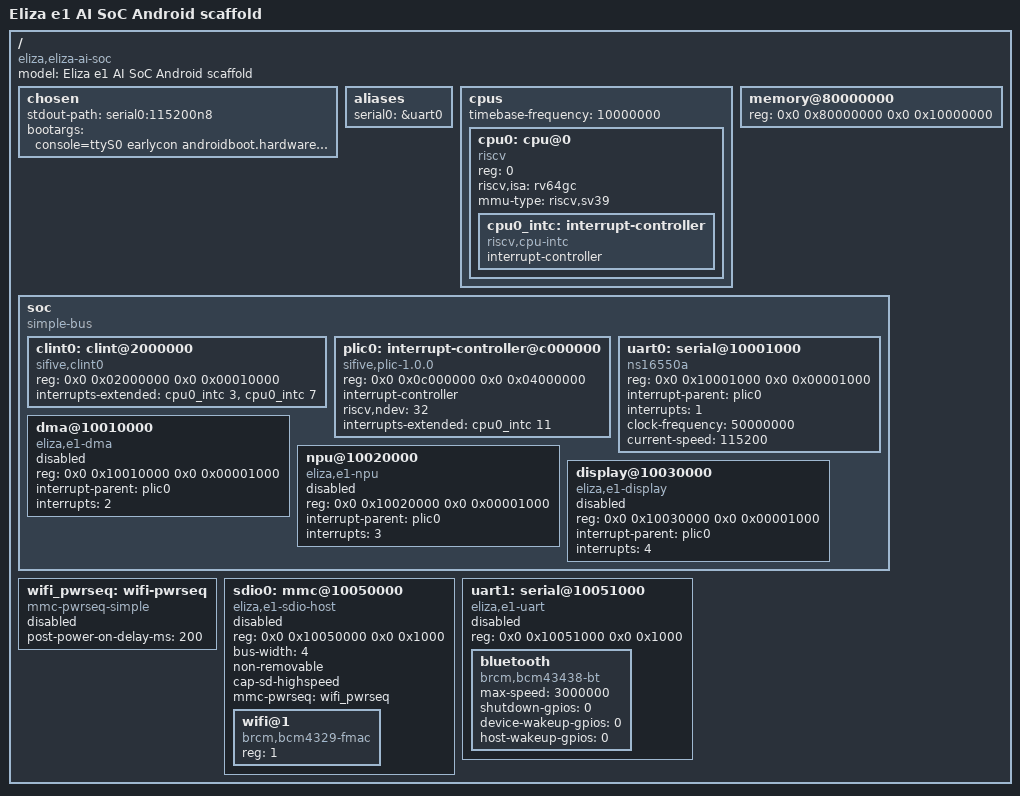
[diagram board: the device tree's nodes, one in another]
/dts-v1/;

/ {
    compatible = "eliza,eliza-ai-soc", "eliza,e1-soc";
    model = "Eliza e1 AI SoC Android scaffold";
    #address-cells = <2>;
    #size-cells = <2>;

    chosen {
        stdout-path = "serial0:115200n8";
        bootargs = "console=ttyS0 earlycon androidboot.hardware=eliza_ai_soc";
    };

    aliases {
        serial0 = &uart0;
    };

    cpus {
        #address-cells = <1>;
        #size-cells = <0>;
        timebase-frequency = <10000000>;

        cpu0: cpu@0 {
            compatible = "riscv";
            device_type = "cpu";
            reg = <0>;
            riscv,isa = "rv64gc";
            mmu-type = "riscv,sv39";
            status = "okay";

            cpu0_intc: interrupt-controller {
                compatible = "riscv,cpu-intc";
                interrupt-controller;
                #interrupt-cells = <1>;
            };
        };
    };

    memory@80000000 {
        device_type = "memory";
        reg = <0x0 0x80000000 0x0 0x10000000>;
    };

    soc {
        compatible = "simple-bus";
        #address-cells = <2>;
        #size-cells = <2>;
        ranges;

        clint0: clint@2000000 {
            compatible = "sifive,clint0", "riscv,clint0";
            reg = <0x0 0x02000000 0x0 0x00010000>;
            interrupts-extended = <&cpu0_intc 3>, <&cpu0_intc 7>;
        };

        plic0: interrupt-controller@c000000 {
            compatible = "sifive,plic-1.0.0", "riscv,plic0";
            reg = <0x0 0x0c000000 0x0 0x04000000>;
            interrupt-controller;
            #address-cells = <0>;
            #interrupt-cells = <1>;
            riscv,ndev = <32>;
            interrupts-extended = <&cpu0_intc 11>;
        };

        uart0: serial@10001000 {
            compatible = "ns16550a";
            reg = <0x0 0x10001000 0x0 0x00001000>;
            interrupt-parent = <&plic0>;
            interrupts = <1>;
            clock-frequency = <50000000>;
            current-speed = <115200>;
            status = "okay";
        };

        dma@10010000 {
            compatible = "eliza,e1-dma";
            reg = <0x0 0x10010000 0x0 0x00001000>;
            interrupt-parent = <&plic0>;
            interrupts = <2>;
            status = "disabled";
        };

        npu@10020000 {
            compatible = "eliza,e1-npu";
            reg = <0x0 0x10020000 0x0 0x00001000>;
            interrupt-parent = <&plic0>;
            interrupts = <3>;
            status = "disabled";
        };

        display@10030000 {
            compatible = "eliza,e1-display";
            reg = <0x0 0x10030000 0x0 0x00001000>;
            interrupt-parent = <&plic0>;
            interrupts = <4>;
            status = "disabled";
        };
    };

    wifi_pwrseq: wifi-pwrseq {
        compatible = "mmc-pwrseq-simple";
        status = "disabled";
        /*
         * Android-facing mirror of the Linux WiFi scaffold. Do not set this
         * node or the SDIO/UART nodes to okay until the board has real GPIO,
         * pinctrl, regulators, IRQ wake, firmware, and regulatory evidence.
         */
        post-power-on-delay-ms = <200>;
    };

    sdio0: mmc@10050000 {
        compatible = "eliza,e1-sdio-host";
        status = "disabled";
        reg = <0x0 0x10050000 0x0 0x1000>;
        #address-cells = <1>;
        #size-cells = <0>;
        bus-width = <4>;
        non-removable;
        cap-sd-highspeed;
        mmc-pwrseq = <&wifi_pwrseq>;

        wifi@1 {
            compatible = "brcm,bcm4329-fmac";
            reg = <1>;
            interrupt-names = "host-wake";
        };
    };

    uart1: serial@10051000 {
        compatible = "eliza,e1-uart";
        status = "disabled";
        reg = <0x0 0x10051000 0x0 0x1000>;

        bluetooth {
            compatible = "brcm,bcm43438-bt";
            max-speed = <3000000>;
            shutdown-gpios = <0>;
            device-wakeup-gpios = <0>;
            host-wakeup-gpios = <0>;
        };
    };
};
